# m52363b register map
Vendor: Elmos Semiconductor SE; Series: Integrated Driver; File version: 1.0
CPU: CM23 r1p0, little endian, MPU, no FPU, VTOR, 2 interrupt priority bits, 13 interrupts
Registers are 16-bit, read-write, reset 0x0 unless marked. A register's access mark holds for its fields unless they carry their own. Offsets are from the block's base; [hi:lo] are bit positions; 'fields as' and 'values as' point back to an identical list.

## SUP — Supply regulator control module
Base 0x50000500
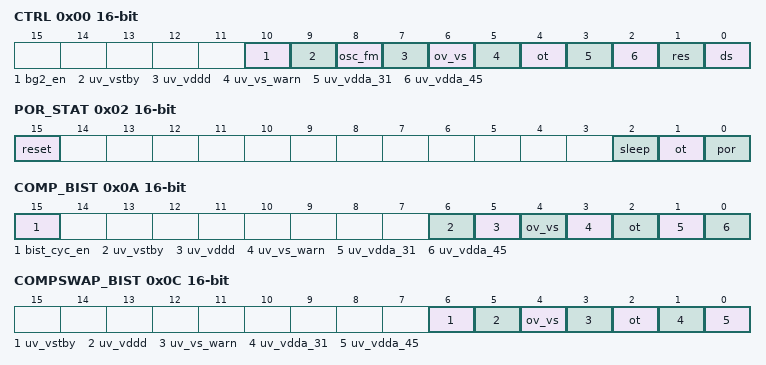
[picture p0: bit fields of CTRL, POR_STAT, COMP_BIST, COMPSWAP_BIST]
0x00 CTRL
  [10] bg2_en — bg2_en bitfield
  [9] uv_vstby — uv_vstby bitfield
  [8] osc_fm — osc_fm bitfield
  [7] uv_vddd — uv_vddd bitfield
  [6] ov_vs — ov_vs bitfield
  [5] uv_vs_warn — uv_vs_warn bitfield
  [4] ot — ot bitfield
  [3] uv_vdda_31 — uv_vdda_31 bitfield
  [2] uv_vdda_45 — uv_vdda_45 bitfield
  [1] res — res bitfield
  [0] ds — ds bitfield
0x02 POR_STAT
  [15] reset — reset bitfield
  [2] sleep ro — sleep bitfield
  [1] ot ro — ot bitfield
  [0] por ro — por bitfield
0x0A COMP_BIST
  [15] bist_cyc_en — bist_cyc_en bitfield
  [6] uv_vstby ro — uv_vstby bitfield
  [5] uv_vddd ro — uv_vddd bitfield
  [4] ov_vs ro — ov_vs bitfield
  [3] uv_vs_warn ro — uv_vs_warn bitfield
  [2] ot ro — ot bitfield
  [1] uv_vdda_31 ro — uv_vdda_31 bitfield
  [0] uv_vdda_45 ro — uv_vdda_45 bitfield
0x0C COMPSWAP_BIST ro
  [6] uv_vstby — uv_vstby bitfield
  [5] uv_vddd — uv_vddd bitfield
  [4] ov_vs — ov_vs bitfield
  [3] uv_vs_warn — uv_vs_warn bitfield
  [2] ot — ot bitfield
  [1] uv_vdda_31 — uv_vdda_31 bitfield
  [0] uv_vdda_45 — uv_vdda_45 bitfield

## SPI — SPI module
Base 0x50000600
0x00 DATA
  [15:0] data — data bitfield
0x02 DATA_KEEP_NSS wo reset not defined
  [15:0] data — data bitfield
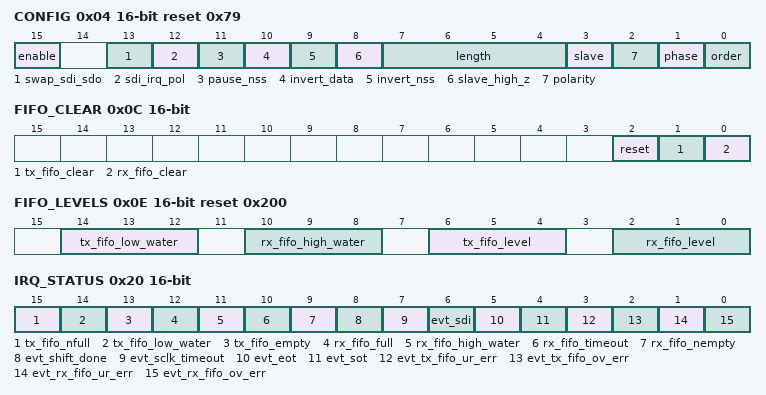
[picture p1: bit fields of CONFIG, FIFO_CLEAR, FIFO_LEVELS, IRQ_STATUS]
0x04 CONFIG reset 0x79
  [15] enable — enable bitfield
  [13] swap_sdi_sdo — swap_sdi_sdo bitfield
  [12] sdi_irq_pol — sdi_irq_pol bitfield
  [11] pause_nss — pause_nss bitfield
  [10] invert_data — invert_data bitfield
  [9] invert_nss — invert_nss bitfield
  [8] slave_high_z — slave_high_z bitfield
  [7:4] length — length bitfield
  [3] slave — slave bitfield
  [2] polarity — polarity bitfield
  [1] phase — phase bitfield
  [0] order — order bitfield
0x06 BAUD_CONFIG
  [15:0] divider — divider bitfield
0x08 TIMEOUT_CONFIG reset 0xFFFF
  [15:0] sclk_timeout — sclk_timeout bitfield
0x0A RX_FIFO_TIMEOUT
  [15:0] rx_fifo_timeout — rx_fifo_timeout bitfield
0x0C FIFO_CLEAR wo reset not defined
  [2] reset — reset bitfield
  [1] tx_fifo_clear — tx_fifo_clear bitfield
  [0] rx_fifo_clear — rx_fifo_clear bitfield
0x0E FIFO_LEVELS reset 0x200
  [14:12] tx_fifo_low_water — tx_fifo_low_water bitfield
  [10:8] rx_fifo_high_water — rx_fifo_high_water bitfield
  [6:4] tx_fifo_level — tx_fifo_level bitfield
  [2:0] rx_fifo_level — rx_fifo_level bitfield
0x20 IRQ_STATUS
  [15] tx_fifo_nfull — tx_fifo_nfull bitfield
  [14] tx_fifo_low_water — tx_fifo_low_water bitfield
  [13] tx_fifo_empty — tx_fifo_empty bitfield
  [12] rx_fifo_full — rx_fifo_full bitfield
  [11] rx_fifo_high_water — rx_fifo_high_water bitfield
  [10] rx_fifo_timeout — rx_fifo_timeout bitfield
  [9] rx_fifo_nempty — rx_fifo_nempty bitfield
  [8] evt_shift_done — evt_shift_done bitfield
  [7] evt_sclk_timeout — evt_sclk_timeout bitfield
  [6] evt_sdi — evt_sdi bitfield
  [5] evt_eot — evt_eot bitfield
  [4] evt_sot — evt_sot bitfield
  [3] evt_tx_fifo_ur_err — evt_tx_fifo_ur_err bitfield
  [2] evt_tx_fifo_ov_err — evt_tx_fifo_ov_err bitfield
  [1] evt_rx_fifo_ur_err — evt_rx_fifo_ur_err bitfield
  [0] evt_rx_fifo_ov_err — evt_rx_fifo_ov_err bitfield
0x24 IRQ_MASK
  [15:0] mask — mask bitfield
0x28 IRQ_VENABLE wo reset not defined
  [3:0] vno — vno bitfield
0x2A IRQ_VDISABLE wo reset not defined
  [3:0] vno — vno bitfield
0x2C IRQ_VMAX reset 0x10
  [4:0] vmax — vmax bitfield
0x2E IRQ_VNO reset 0x10
  [4:0] vno — vno bitfield

## CCT — Capture compare control module (SENT)
Base 0x50000700
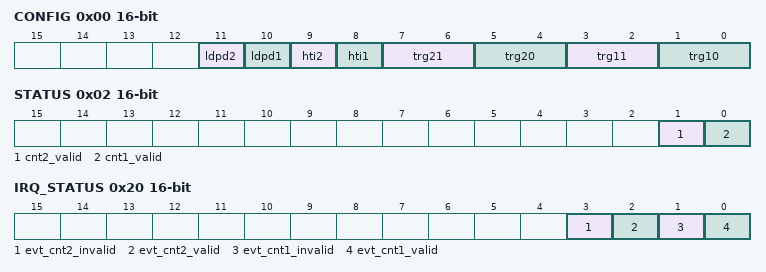
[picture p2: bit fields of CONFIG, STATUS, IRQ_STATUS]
0x00 CONFIG
  [11] ldpd2 — ldpd2 bitfield
  [10] ldpd1 — ldpd1 bitfield
  [9] hti2 — hti2 bitfield
  [8] hti1 — hti1 bitfield
  [7:6] trg21 — trg21 bitfield
  [5:4] trg20 — trg20 bitfield
  [3:2] trg11 — trg11 bitfield
  [1:0] trg10 — trg10 bitfield
0x02 STATUS ro
  [1] cnt2_valid — cnt2_valid bitfield
  [0] cnt1_valid — cnt1_valid bitfield
0x04 PRE_DIV1 reset 0x1
  [11:0] val — val bitfield
0x06 CNT1 ro
  [11:0] val — val bitfield
0x08 CNT1MIN
  [11:0] val — val bitfield
0x0A CNT1MAX
  [11:0] val — val bitfield
0x0C PRE_DIV2
  [11:0] val — val bitfield
0x0E CNT2 ro
  [11:0] val — val bitfield
0x10 CNT2MIN
  [11:0] val — val bitfield
0x12 CNT2MAX
  [11:0] val — val bitfield
0x20 IRQ_STATUS
  [3] evt_cnt2_invalid — evt_cnt2_invalid bitfield
  [2] evt_cnt2_valid — evt_cnt2_valid bitfield
  [1] evt_cnt1_invalid — evt_cnt1_invalid bitfield
  [0] evt_cnt1_valid — evt_cnt1_valid bitfield
0x24 IRQ_MASK
  [3:0] mask — mask bitfield
0x28 IRQ_VENABLE wo reset not defined
  [1:0] vno — vno bitfield
0x2A IRQ_VDISABLE wo reset not defined
  [1:0] vno — vno bitfield
0x2C IRQ_VMAX reset 0x4
  [2:0] vmax — vmax bitfield
0x2E IRQ_VNO reset 0x4
  [2:0] vno — vno bitfield

## LIN_CTRL — LIN_CTRL module
Base 0x51000100
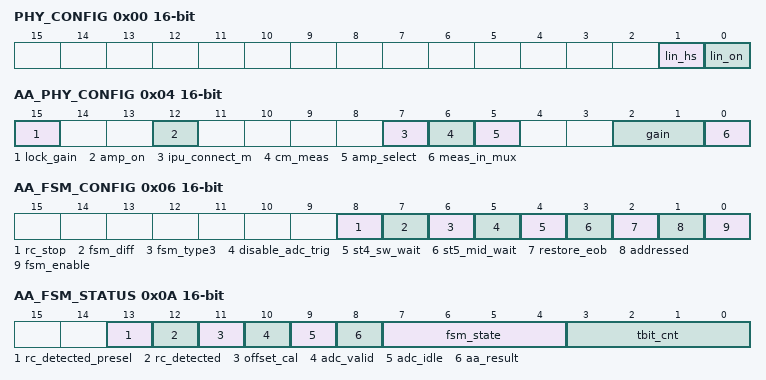
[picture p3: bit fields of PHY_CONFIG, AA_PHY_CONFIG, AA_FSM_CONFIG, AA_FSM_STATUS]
0x00 PHY_CONFIG
  [1] lin_hs — lin_hs bitfield
  [0] lin_on — lin_on bitfield
0x04 AA_PHY_CONFIG
  [15] lock_gain — lock_gain bitfield
  [12] amp_on — amp_on bitfield
  [7] ipu_connect_m — ipu_connect_m bitfield
  [6] cm_meas — cm_meas bitfield
  [5] amp_select — amp_select bitfield
  [2:1] gain — gain bitfield
  [0] meas_in_mux — meas_in_mux bitfield
0x06 AA_FSM_CONFIG
  [8] rc_stop — rc_stop bitfield
  [7] fsm_diff — fsm_diff bitfield
  [6] fsm_type3 — fsm_type3 bitfield
  [5] disable_adc_trig — disable_adc_trig bitfield
  [4] st4_sw_wait — st4_sw_wait bitfield
  [3] st5_mid_wait — st5_mid_wait bitfield
  [2] restore_eob — restore_eob bitfield
  [1] addressed — addressed bitfield
  [0] fsm_enable — fsm_enable bitfield
0x08 AA_FSM_CONTROL wo reset not defined
  [0] st4_sw_proceed — st4_sw_proceed bitfield
0x0A AA_FSM_STATUS ro
  [13] rc_detected_presel — rc_detected_presel bitfield
  [12] rc_detected — rc_detected bitfield
  [11] offset_cal — offset_cal bitfield
  [10] adc_valid — adc_valid bitfield
  [9] adc_idle — adc_idle bitfield
  [8] aa_result — aa_result bitfield
  [7:4] fsm_state — fsm_state bitfield
  [3:0] tbit_cnt — tbit_cnt bitfield
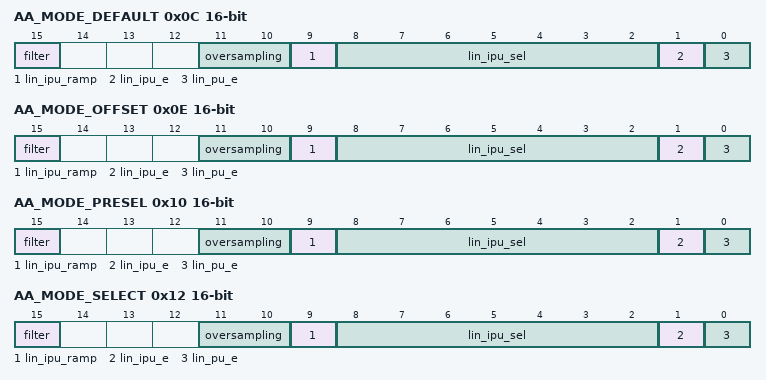
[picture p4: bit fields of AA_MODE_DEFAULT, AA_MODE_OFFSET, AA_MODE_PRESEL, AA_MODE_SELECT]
0x0C AA_MODE_DEFAULT
  [15] filter — filter bitfield
  [11:10] oversampling — oversampling bitfield
  [9] lin_ipu_ramp — lin_ipu_ramp bitfield
  [8:2] lin_ipu_sel — lin_ipu_sel bitfield
  [1] lin_ipu_e — lin_ipu_e bitfield
  [0] lin_pu_e — lin_pu_e bitfield
0x0E AA_MODE_OFFSET
  fields as AA_MODE_DEFAULT
0x10 AA_MODE_PRESEL
  fields as AA_MODE_DEFAULT
0x12 AA_MODE_SELECT
  fields as AA_MODE_DEFAULT
0x14 AA_ADC_RESULT
  [11:0] result — result bitfield
0x16 AA_I_DIFF_THD_1
  [11:0] i_diff_thd_1 — i_diff_thd_1 bitfield
0x18 AA_I_DIFF_THD_2
  [11:0] i_diff_thd_2 — i_diff_thd_2 bitfield
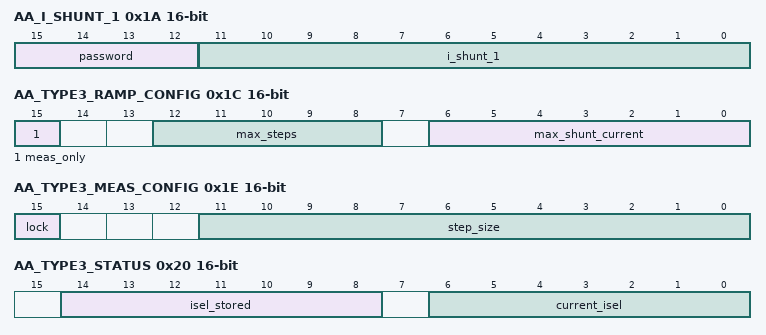
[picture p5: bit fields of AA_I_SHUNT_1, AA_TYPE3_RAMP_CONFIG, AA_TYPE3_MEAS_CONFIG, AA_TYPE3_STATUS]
0x1A AA_I_SHUNT_1
  [15:12] password — password bitfield
  [11:0] i_shunt_1 — i_shunt_1 bitfield
0x1C AA_TYPE3_RAMP_CONFIG
  [15] meas_only — meas_only bitfield
  [12:8] max_steps — max_steps bitfield
  [6:0] max_shunt_current — max_shunt_current bitfield
0x1E AA_TYPE3_MEAS_CONFIG
  [15] lock — lock bitfield
  [11:0] step_size — step_size bitfield
0x20 AA_TYPE3_STATUS ro
  [14:8] isel_stored — isel_stored bitfield
  [6:0] current_isel — current_isel bitfield
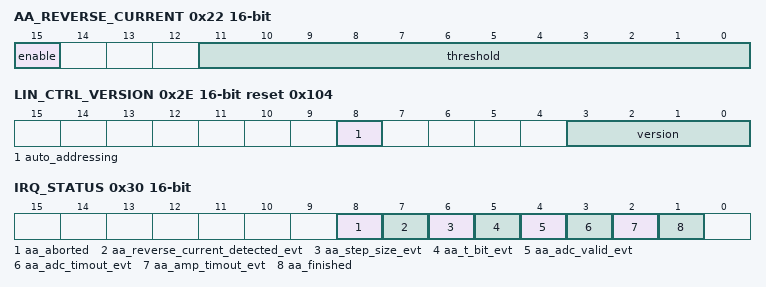
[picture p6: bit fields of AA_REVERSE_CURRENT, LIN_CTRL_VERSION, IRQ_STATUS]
0x22 AA_REVERSE_CURRENT
  [15] enable — enable bitfield
  [11:0] threshold — threshold bitfield
0x2C AA_REVERSE_CURRENT_PRESEL reset 0xFFF
  [11:0] threshold_presel — threshold_presel bitfield
0x2E LIN_CTRL_VERSION ro reset 0x104
  [8] auto_addressing — auto_addressing bitfield
  [3:0] version — version bitfield
0x30 IRQ_STATUS
  [8] aa_aborted — aa_aborted bitfield
  [7] aa_reverse_current_detected_evt — aa_reverse_current_detected_evt bitfield
  [6] aa_step_size_evt — aa_step_size_evt bitfield
  [5] aa_t_bit_evt — aa_t_bit_evt bitfield
  [4] aa_adc_valid_evt — aa_adc_valid_evt bitfield
  [3] aa_adc_timout_evt — aa_adc_timout_evt bitfield
  [2] aa_amp_timout_evt — aa_amp_timout_evt bitfield
  [1] aa_finished — aa_finished bitfield
0x34 IRQ_MASK
  [8:0] mask — mask bitfield
0x38 IRQ_VENABLE wo reset not defined
  [3:0] vno — vno bitfield
0x3A IRQ_VDISABLE wo reset not defined
  [3:0] vno — vno bitfield
0x3C IRQ_VMAX reset 0x9
  [3:0] vmax — vmax bitfield
0x3E IRQ_VNO reset 0x9
  [3:0] vno — vno bitfield
